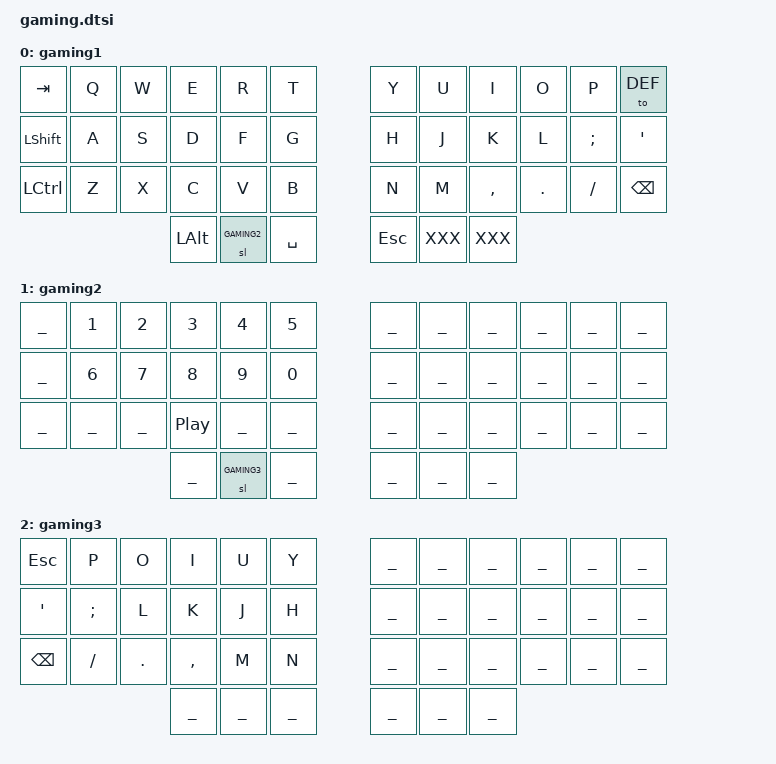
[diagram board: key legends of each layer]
ZMK_LAYER(gaming1,
//╭─────────────┬─────────────┬─────────────┬─────────────┬─────────────┬─────────────╮ ╭─────────────┬─────────────┬─────────────┬─────────────┬─────────────┬─────────────╮
    &kp TAB       &kp Q         &kp W         &kp E         &kp R         &kp T           &kp Y         &kp U         &kp I         &kp O         &kp P         &to DEF
//├─────────────┼─────────────┼─────────────┼─────────────┼─────────────┼─────────────┤ ├─────────────┼─────────────┼─────────────┼─────────────┼─────────────┼─────────────┤
    &kp LSHFT     &kp A         &kp S         &kp D         &kp F         &kp G           &kp H         &kp J         &kp K         &kp L         &kp SEMI      &kp SQT
//├─────────────┼─────────────┼─────────────┼─────────────┼─────────────┼─────────────┤ ├─────────────┼─────────────┼─────────────┼─────────────┼─────────────┼─────────────┤
    &kp LCTRL     &kp Z         &kp X         &kp C         &kp V         &kp B           &kp N         &kp M         &kp COMMA     &kp DOT       &kp FSLH      &kp BSPC
//╰─────────────┴─────────────┴─────────────┼─────────────┼─────────────┼─────────────┤ ├─────────────┼─────────────┼─────────────┼─────────────┴─────────────┴─────────────╯
                                              &kp LALT      &sl GAMING2   &kp SPACE       &kp ESC       XXX           XXX
//                                          ╰─────────────┴─────────────┴─────────────╯ ╰─────────────┴─────────────┴─────────────╯
)

ZMK_LAYER(gaming2,
//╭─────────────┬─────────────┬─────────────┬─────────────┬─────────────┬─────────────╮ ╭─────────────┬─────────────┬─────────────┬─────────────┬─────────────┬─────────────╮
    ___           &kp N1        &kp N2        &kp N3        &kp N4        &kp N5          ___           ___           ___           ___           ___           ___
//├─────────────┼─────────────┼─────────────┼─────────────┼─────────────┼─────────────┤ ├─────────────┼─────────────┼─────────────┼─────────────┼─────────────┼─────────────┤
    ___           &kp N6        &kp N7        &kp N8        &kp N9        &kp N0          ___           ___           ___           ___           ___           ___
//├─────────────┼─────────────┼─────────────┼─────────────┼─────────────┼─────────────┤ ├─────────────┼─────────────┼─────────────┼─────────────┼─────────────┼─────────────┤
    ___           ___           ___           &kp C_PP      ___           ___             ___           ___           ___           ___           ___           ___
//╰─────────────┴─────────────┴─────────────┼─────────────┼─────────────┼─────────────┤ ├─────────────┼─────────────┼─────────────┼─────────────┴─────────────┴─────────────╯
                                              ___           &sl GAMING3   ___             ___           ___           ___
//                                          ╰─────────────┴─────────────┴─────────────╯ ╰─────────────┴─────────────┴─────────────╯
)

ZMK_LAYER(gaming3,
//╭─────────────┬─────────────┬─────────────┬─────────────┬─────────────┬─────────────╮ ╭─────────────┬─────────────┬─────────────┬─────────────┬─────────────┬─────────────╮
    &kp ESC       &kp P         &kp O         &kp I         &kp U         &kp Y           ___           ___           ___           ___           ___           ___
//├─────────────┼─────────────┼─────────────┼─────────────┼─────────────┼─────────────┤ ├─────────────┼─────────────┼─────────────┼─────────────┼─────────────┼─────────────┤
    &kp SQT       &kp SEMI      &kp L         &kp K         &kp J         &kp H           ___           ___           ___           ___           ___           ___
//├─────────────┼─────────────┼─────────────┼─────────────┼─────────────┼─────────────┤ ├─────────────┼─────────────┼─────────────┼─────────────┼─────────────┼─────────────┤
    &kp BSPC      &kp FSLH      &kp DOT       &kp COMMA     &kp M         &kp N           ___           ___           ___           ___           ___           ___
//╰─────────────┴─────────────┴─────────────┼─────────────┼─────────────┼─────────────┤ ├─────────────┼─────────────┼─────────────┼─────────────┴─────────────┴─────────────╯
                                              ___           ___           ___             ___           ___           ___
//                                          ╰─────────────┴─────────────┴─────────────╯ ╰─────────────┴─────────────┴─────────────╯
)

#include "minecraft.dtsi"
#include "god_of_war.dtsi"
#include "monster_hunter_wilds.dtsi"
#include "ror2.dtsi"

#define ZMK_LAYER_RESERVED(_name) \
    / { \
        keymap { \
            compatible = "zmk,keymap"; \
            layer_ ## _name { \
                status = "reserved"; \
            }; \
        }; \
    };

ZMK_LAYER_RESERVED(extra1)
ZMK_LAYER_RESERVED(extra2)
ZMK_LAYER_RESERVED(extra3)
ZMK_LAYER_RESERVED(extra4)
ZMK_LAYER_RESERVED(extra5)

